VERSION ""

NS_ :

BS_:

BU_: BMS_Ext
VAL_TABLE_ BHVB_State_IMDwarning 1 "IMD未报警" 0 "IMD报警" ;
VAL_TABLE_ BHVB_State_FZ 1 "互锁断开" 0 "互锁闭合" ;
VAL_TABLE_ BHVB_State_HV 1 "电压大于50.2V" 0 "电压小于50.2V" ;
VAL_TABLE_ BHVB_State_intention 1 "意向检测闭合" 0 "意向检测断开" ;
VAL_TABLE_ BHVB_State_BMSwarning 1 "BMS未报警" 0 "BMS报警" ;
VAL_TABLE_ BMS_Cooling_Heating_ValTable 1 "Active" 0 "Inactive" ;
VAL_TABLE_ BatAlmLv_ValTab 3 "3级告警" 2 "2级告警" 1 "1级告警 断电" 0 "无告警" ;
VAL_TABLE_ BatState_ValTab 7 "错误状态" 6 "关机状态" 5 "运行状态" 4 "预充状态" 3 "待机状态" 2 "自检状态" 1 "休眠状态" ;

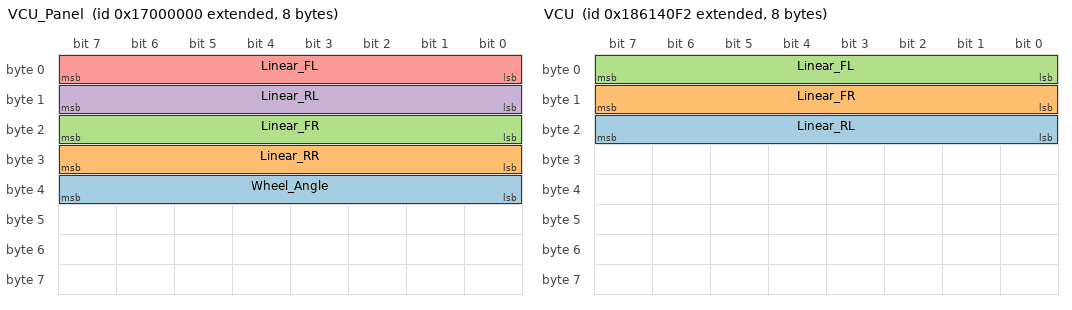
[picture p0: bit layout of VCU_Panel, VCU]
BO_ 2533359616 VCU_Panel: 8 Vector__XXX
 SG_ Wheel_Angle : 32|8@1- (1,0) [0|5000] "" Vector__XXX
 SG_ Linear_RR : 24|8@1- (1,0) [0|5000] "" Vector__XXX
 SG_ Linear_FR : 16|8@1- (1,0) [0|5000] "" Vector__XXX
 SG_ Linear_RL : 8|8@1- (1,0) [0|5000] "" Vector__XXX
 SG_ Linear_FL : 0|8@1- (1,0) [0|5000] "" Vector__XXX

BO_ 2556510450 VCU: 8 Vector__XXX
 SG_ Linear_RL : 16|8@1- (1,0) [0|0] "" Vector__XXX
 SG_ Linear_FR : 8|8@1- (1,0) [0|0] "" Vector__XXX
 SG_ Linear_FL : 0|8@1- (1,0) [0|0] "" Vector__XXX

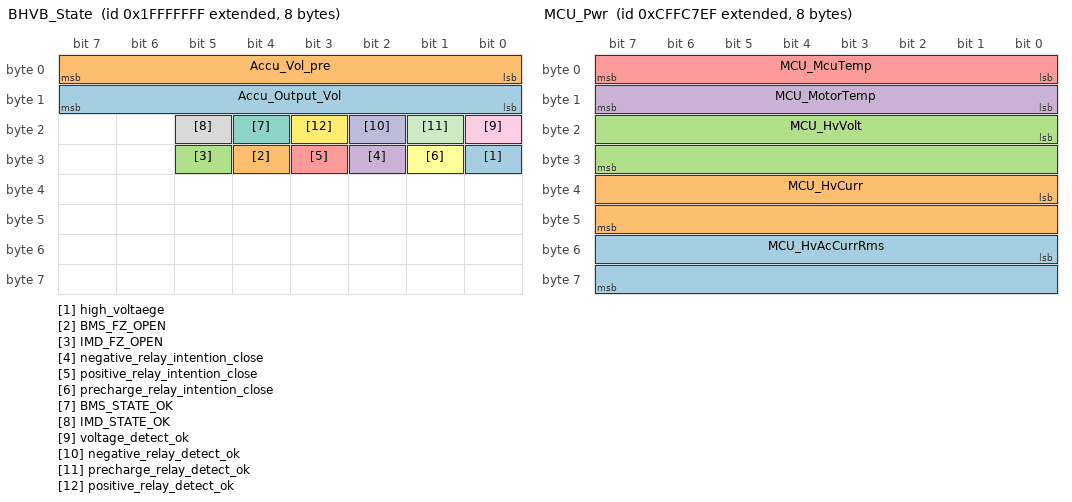
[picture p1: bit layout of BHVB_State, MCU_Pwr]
BO_ 2684354559 BHVB_State: 8 Vector__XXX
 SG_ high_voltaege : 24|1@1- (1,0) [0|0] "" Vector__XXX
 SG_ BMS_FZ_OPEN : 28|1@1- (1,0) [0|0] "" Vector__XXX
 SG_ IMD_FZ_OPEN : 29|1@1- (1,0) [0|0] "" Vector__XXX
 SG_ negative_relay_intention_close : 26|1@1- (1,0) [0|0] "" Vector__XXX
 SG_ positive_relay_intention_close : 27|1@1- (1,0) [0|0] "" Vector__XXX
 SG_ precharge_relay_intention_close : 25|1@1- (1,0) [0|0] "" Vector__XXX
 SG_ BMS_STATE_OK : 20|1@1- (1,0) [0|0] "" Vector__XXX
 SG_ IMD_STATE_OK : 21|1@1- (1,0) [0|0] "" Vector__XXX
 SG_ voltage_detect_ok : 16|1@1- (1,0) [0|0] "" Vector__XXX
 SG_ negative_relay_detect_ok : 18|1@1- (1,0) [0|0] "" Vector__XXX
 SG_ precharge_relay_detect_ok : 17|1@1- (1,0) [0|0] "" Vector__XXX
 SG_ positive_relay_detect_ok : 19|1@1- (1,0) [0|0] "" Vector__XXX
 SG_ Accu_Output_Vol : 8|8@1- (4.9,0) [0|0] "" Vector__XXX
 SG_ Accu_Vol_pre : 0|8@1- (4.9,0) [0|0] "" Vector__XXX

BO_ 2556772595 BMS_HCU_ALM: 8 Vector__XXX
 SG_ BMS_ALM_VCU_OFFLINE : 32|2@1+ (1,0) [0|3] "" Vector__XXX
 SG_ BMS_ALM_PRECHG_FAIL : 36|1@1+ (1,0) [0|3] "" Vector__XXX
 SG_ BMS_ALM_LEAK_OC : 37|2@1+ (1,0) [0|3] "" Vector__XXX
 SG_ BMS_ALM_HVREL_FAIL : 47|1@1+ (1,0) [0|3] "" Vector__XXX
 SG_ BMS_ALM_HALL_BREAK : 46|1@1+ (1,0) [0|3] "" Vector__XXX
 SG_ BMS_ALM_DSCH_OCT : 26|2@1+ (1,0) [0|3] "" Vector__XXX
 SG_ BMS_ALM_DSCH_OCS : 30|2@1+ (1,0) [0|3] "" Vector__XXX
 SG_ BMS_ALM_CHRG_OCT : 28|2@1+ (1,0) [0|3] "" Vector__XXX
 SG_ BMS_ALM_CHRG_OCS : 16|2@1+ (1,0) [0|3] "" Vector__XXX
 SG_ BMS_ALM_CELL_UV : 4|2@1+ (1,0) [0|3] "" Vector__XXX
 SG_ BMS_ALM_CELL_UT : 0|2@1+ (1,0) [0|3] "" Vector__XXX
 SG_ BMS_ALM_CELL_TBK : 14|1@1+ (1,0) [0|3] "" Vector__XXX
 SG_ BMS_ALM_CELL_OV : 6|2@1+ (1,0) [0|3] "" Vector__XXX
 SG_ BMS_ALM_CELL_OT : 2|2@1+ (1,0) [0|3] "" Vector__XXX
 SG_ BMS_ALM_CELL_LBK : 15|1@1+ (1,0) [0|3] "" Vector__XXX
 SG_ BMS_ALM_CELL_DV : 12|2@1+ (1,0) [0|3] "" Vector__XXX
 SG_ BMS_ALM_CELL_DT : 10|2@1+ (1,0) [0|3] "" Vector__XXX
 SG_ BMS_ALM_BSU_OFFLINE : 24|2@1+ (1,0) [0|3] "" Vector__XXX
 SG_ BMS_ALM_BSU_FAULT : 39|1@1+ (1,0) [0|3] "" Vector__XXX
 SG_ BMS_ALM_BMU_FAIL : 34|1@1+ (1,0) [0|3] "" Vector__XXX
 SG_ BMS_ALM_BATT_UV : 22|2@1+ (1,0) [0|3] "" Vector__XXX
 SG_ BMS_ALM_BATT_UC : 18|2@1+ (1,0) [0|3] "" Vector__XXX
 SG_ BMS_ALM_BATT_OV : 8|2@1+ (1,0) [0|3] "" Vector__XXX
 SG_ BMS_ALM_BATT_OC : 20|2@1+ (1,0) [0|3] "" Vector__XXX
 SG_ BMS_ALM_AUX_FAIL : 35|1@1+ (1,0) [0|3] "" Vector__XXX

BO_ 2365573103 MCU_Pwr: 8 Vector__XXX
 SG_ MCU_HvAcCurrRms : 48|16@1+ (0.1,-1600) [-1600|1600] "" Vector__XXX
 SG_ MCU_HvCurr : 32|16@1+ (0.1,-1600) [-1600|1600] "" Vector__XXX
 SG_ MCU_HvVolt : 16|16@1+ (0.1,0) [0|1000] "Volt" Vector__XXX
 SG_ MCU_MotorTemp : 8|8@1+ (1,-50) [-50|205] "" Vector__XXX
 SG_ MCU_McuTemp : 0|8@1+ (1,-50) [-50|205] "celcius" Vector__XXX

BO_ 2365572847 MCU_Stat: 8 Vector__XXX
 SG_ MCU_AlmLv : 56|2@1+ (1,0) [0|3] "" Vector__XXX
 SG_ MCU_IsSelfcheckPass : 55|1@1+ (1,0) [0|1] "" Vector__XXX
 SG_ MCU_IsMotorOvertemp : 49|1@1+ (1,0) [0|1] "" Vector__XXX
 SG_ MCU_IsMcuOvertemp : 48|1@1+ (1,0) [0|1] "" Vector__XXX
 SG_ MCU_IsUnderPowerLim : 47|1@1+ (1,0) [0|1] "" Vector__XXX
 SG_ MCU_IsHvUndervoltage : 46|1@1+ (1,0) [0|1] "" Vector__XXX
 SG_ MCU_IsLvError : 45|1@1+ (1,0) [0|1] "" Vector__XXX
 SG_ MCU_IsHvOvervoltage : 44|1@1+ (1,0) [0|1] "" Vector__XXX
 SG_ MCU_IsOverCurr : 43|1@1+ (1,0) [0|1] "" Vector__XXX
 SG_ MCU_IsRevoloverError : 42|1@1+ (1,0) [0|1] "" Vector__XXX
 SG_ MCU_IsPreChg : 41|1@1+ (1,0) [0|255] "" Vector__XXX
 SG_ MCU_IsReady : 40|1@1+ (1,0) [0|1] "" Vector__XXX
 SG_ MCU_IsMcuNOTActive : 39|1@1+ (1,0) [0|1] "" Vector__XXX
 SG_ MCU_IsZeroLocMode : 36|1@1+ (1,0) [0|1] "" Vector__XXX
 SG_ MCU_IsBrakeMode : 35|1@1+ (1,0) [0|1] "" Vector__XXX
 SG_ MCU_IsSpdMode : 34|1@1+ (1,0) [0|1] "" Vector__XXX
 SG_ MCU_IsTorqMode : 33|1@1+ (1,0) [0|1] "" Vector__XXX
 SG_ MCU_IsFreeMode : 32|1@1+ (1,0) [0|1] "" Vector__XXX
 SG_ MCU_TORQ_RPT : 16|16@1+ (1,0) [0|1000] "1/1000" Vector__XXX
 SG_ MCU_SPD_RPT : 0|16@1+ (0.5,-10000) [-10000|10000] "rpm" Vector__XXX

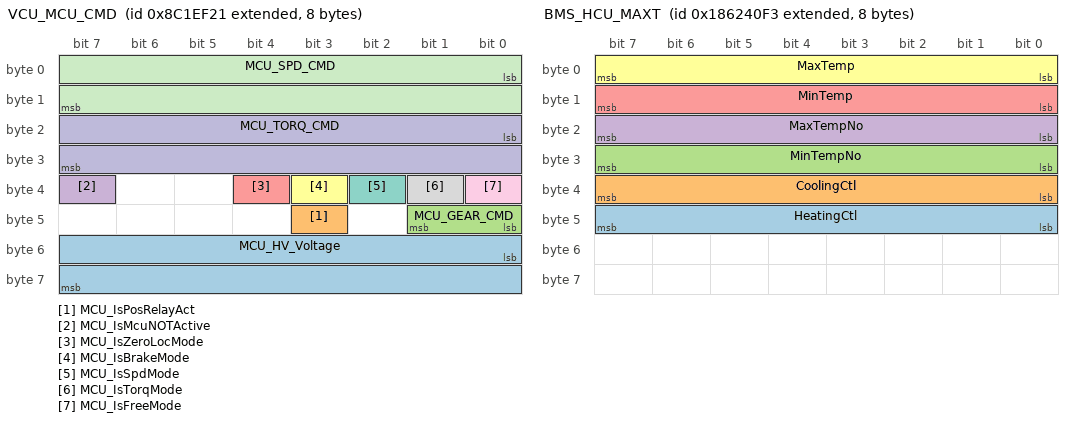
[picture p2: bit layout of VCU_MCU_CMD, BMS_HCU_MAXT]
BO_ 2294411041 VCU_MCU_CMD: 8 Vector__XXX
 SG_ MCU_HV_Voltage : 48|16@1+ (0.1,0) [0|1000] "" Vector__XXX
 SG_ MCU_IsPosRelayAct : 43|1@1+ (1,0) [0|1] "" Vector__XXX
 SG_ MCU_GEAR_CMD : 40|2@1+ (1,0) [0|3] "" Vector__XXX
 SG_ MCU_IsMcuNOTActive : 39|1@1+ (1,0) [0|1] "" Vector__XXX
 SG_ MCU_IsZeroLocMode : 36|1@1+ (1,0) [0|1] "" Vector__XXX
 SG_ MCU_IsBrakeMode : 35|1@1+ (1,0) [0|1] "" Vector__XXX
 SG_ MCU_IsSpdMode : 34|1@1+ (1,0) [0|1] "" Vector__XXX
 SG_ MCU_IsTorqMode : 33|1@1+ (1,0) [0|1] "" Vector__XXX
 SG_ MCU_IsFreeMode : 32|1@1+ (1,0) [0|1] "" Vector__XXX
 SG_ MCU_TORQ_CMD : 16|16@1+ (1,0) [0|1000] "1/1000" Vector__XXX
 SG_ MCU_SPD_CMD : 0|16@1+ (0.5,-10000) [-10000|10000] "rpm" Vector__XXX

BO_ 2556575987 BMS_HCU_MAXT: 8 Vector__XXX
 SG_ HeatingCtl : 47|8@0+ (1,0) [0|1] "" Vector__XXX
 SG_ CoolingCtl : 39|8@0+ (1,0) [0|1] "" Vector__XXX
 SG_ MinTempNo : 31|8@0+ (1,0) [0|255] "" Vector__XXX
 SG_ MaxTempNo : 23|8@0+ (1,0) [0|255] "" Vector__XXX
 SG_ MinTemp : 15|8@0+ (1,-40) [-40|120] "Celsius" Vector__XXX
 SG_ MaxTemp : 7|8@0+ (1,-40) [-40|120] "Celsius" Vector__XXX

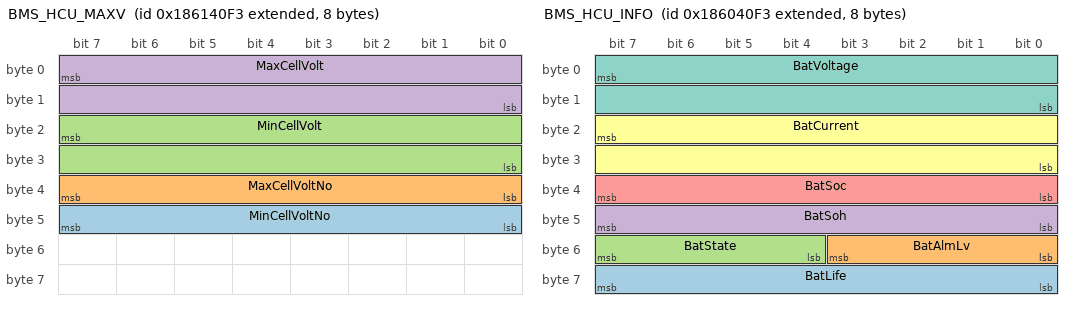
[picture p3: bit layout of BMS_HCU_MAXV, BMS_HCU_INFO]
BO_ 2556510451 BMS_HCU_MAXV: 8 Vector__XXX
 SG_ MinCellVoltNo : 47|8@0+ (1,0) [0|255] "miliVolt" Vector__XXX
 SG_ MaxCellVoltNo : 39|8@0+ (1,0) [0|255] "miliVolt" Vector__XXX
 SG_ MinCellVolt : 23|16@0+ (1,0) [0|5000] "miliVolt" Vector__XXX
 SG_ MaxCellVolt : 7|16@0+ (1,0) [0|5000] "miliVolt" Vector__XXX

BO_ 2556444915 BMS_HCU_INFO: 8 BMS_Ext
 SG_ BatLife : 63|8@0+ (1,0) [0|255] "cycle" Vector__XXX
 SG_ BatAlmLv : 51|4@0+ (1,0) [0|4] "" Vector__XXX
 SG_ BatState : 55|4@0+ (1,0) [0|7] "" Vector__XXX
 SG_ BatSoh : 47|8@0+ (1,0) [0|100] "%" Vector__XXX
 SG_ BatSoc : 39|8@0+ (1,0) [0|100] "%" Vector__XXX
 SG_ BatCurrent : 23|16@0+ (0.1,-1000) [-1000|1000] "Amps" Vector__XXX
 SG_ BatVoltage : 7|16@0+ (0.1,0) [0|900] "Volt" Vector__XXX

CM_ SG_ 2684354559 high_voltaege "电池箱两端电压大于50.2V";
CM_ SG_ 2684354559 BMS_FZ_OPEN "BMS安全回路断开";
CM_ SG_ 2684354559 IMD_FZ_OPEN "IMD安全回路断开
";
CM_ SG_ 2684354559 negative_relay_intention_close "主正继电器意向状态";
CM_ SG_ 2684354559 positive_relay_intention_close "主正继电器意向状态";
CM_ SG_ 2684354559 precharge_relay_intention_close "预充继电器意向状态
";
CM_ SG_ 2684354559 BMS_STATE_OK "BMS Warning
";
CM_ SG_ 2684354559 IMD_STATE_OK "IMD warning";
CM_ SG_ 2684354559 voltage_detect_ok "电压检测电路正常
";
CM_ SG_ 2684354559 negative_relay_detect_ok "主负继电器检测电路正常";
CM_ SG_ 2684354559 precharge_relay_detect_ok "预充继电器检测电路正常";
CM_ SG_ 2684354559 positive_relay_detect_ok "主正继电器检测电路正常";
CM_ SG_ 2684354559 Accu_Output_Vol "电池箱输出电压（主正继电器外侧和主负继电器外侧）";
CM_ SG_ 2684354559 Accu_Vol_pre "电池箱两端电压（预充继电器外侧与主负继电器内侧）";
CM_ SG_ 2365572847 MCU_IsMcuNOTActive "是否为自由模式";
CM_ SG_ 2365572847 MCU_IsZeroLocMode "是否为自由模式";
CM_ SG_ 2365572847 MCU_IsBrakeMode "是否为自由模式";
CM_ SG_ 2365572847 MCU_IsSpdMode "是否为自由模式";
CM_ SG_ 2365572847 MCU_IsTorqMode "是否为自由模式";
CM_ SG_ 2365572847 MCU_IsFreeMode "是否为自由模式";
CM_ SG_ 2365572847 MCU_TORQ_RPT "VCU发送电机转矩指令";
CM_ SG_ 2365572847 MCU_SPD_RPT "VCU发送电机转速指令";
CM_ SG_ 2294411041 MCU_IsPosRelayAct "是否为自由模式";
CM_ SG_ 2294411041 MCU_GEAR_CMD "是否为自由模式";
CM_ SG_ 2294411041 MCU_IsMcuNOTActive "是否为自由模式";
CM_ SG_ 2294411041 MCU_IsZeroLocMode "是否为自由模式";
CM_ SG_ 2294411041 MCU_IsBrakeMode "是否为自由模式";
CM_ SG_ 2294411041 MCU_IsSpdMode "是否为自由模式";
CM_ SG_ 2294411041 MCU_IsTorqMode "是否为自由模式";
CM_ SG_ 2294411041 MCU_IsFreeMode "是否为自由模式";
CM_ SG_ 2294411041 MCU_TORQ_CMD "VCU发送电机转矩指令";
CM_ SG_ 2294411041 MCU_SPD_CMD "VCU发送电机转速指令";
CM_ BO_ 2556575987 "单体温度最值";
CM_ SG_ 2556575987 HeatingCtl "BMS加热状态";
CM_ SG_ 2556575987 CoolingCtl "BMS冷却状态";
CM_ SG_ 2556575987 MinTempNo "最低温度序号";
CM_ SG_ 2556575987 MaxTempNo "最高温度序号";
CM_ SG_ 2556575987 MinTemp "电池单体最低温度";
CM_ SG_ 2556575987 MaxTemp "电池单体最高温度";
CM_ BO_ 2556510451 "单体电压最值";
CM_ SG_ 2556510451 MinCellVoltNo "最低单体电压序号";
CM_ SG_ 2556510451 MaxCellVoltNo "最高单体电压序号";
CM_ SG_ 2556510451 MinCellVolt "最低单体电压";
CM_ SG_ 2556510451 MaxCellVolt "最高单体电压";
CM_ BO_ 2556444915 "BMS信息";
CM_ SG_ 2556444915 BatLife "通信生命信息 通信一次++1";
CM_ SG_ 2556444915 BatAlmLv "动力电池告警级别";
CM_ SG_ 2556444915 BatState "动力电池状态";
CM_ SG_ 2556444915 BatSoh "动力电池SOH";
CM_ SG_ 2556444915 BatSoc "动力电池SOC";
CM_ SG_ 2556444915 BatCurrent "动力电池电流";
CM_ SG_ 2556444915 BatVoltage "动力电池总电压";
BA_DEF_ SG_  "SigType" ENUM  "Default","Range","RangeSigned","ASCII","Discrete","Control","ReferencePGN","DTC","StringDelimiter","StringLength","StringLengthControl","MessageCounter","MessageChecksum";
BA_DEF_ SG_  "GenSigEVName" STRING ;
BA_DEF_ SG_  "GenSigILSupport" ENUM  "No","Yes";
BA_DEF_ SG_  "GenSigSendType" ENUM  "Cyclic","OnWrite","OnWriteWithRepetition","OnChange","OnChangeWithRepetition","IfActive","IfActiveWithRepetition","NoSigSendType";
BA_DEF_ SG_  "GenSigStartValue" INT 0 2147483647;
BA_DEF_ BO_  "GenMsgILSupport" ENUM  "No","Yes";
BA_DEF_ BU_  "NmStationAddress" INT 0 255;
BA_DEF_ BO_  "GenMsgSendType" ENUM  "cyclic","NotUsed","IfActive","NotUsed","NotUsed","NotUsed","NotUsed","NotUsed","noMsgSendType";
BA_DEF_ BO_  "GenMsgRequestable" INT 0 1;
BA_DEF_ BO_  "GenMsgCycleTime" INT 0 3600000;
BA_DEF_  "DBName" STRING ;
BA_DEF_  "BusType" STRING ;
BA_DEF_  "ProtocolType" STRING ;
BA_DEF_ BO_  "VFrameFormat" ENUM  "StandardCAN","ExtendedCAN","reserved","J1939PG";
BA_DEF_DEF_  "SigType" "Default";
BA_DEF_DEF_  "GenSigEVName" "Env@Nodename_@Signame";
BA_DEF_DEF_  "GenSigILSupport" "Yes";
BA_DEF_DEF_  "GenSigSendType" "NoSigSendType";
BA_DEF_DEF_  "GenSigStartValue" 0;
BA_DEF_DEF_  "GenMsgILSupport" "Yes";
BA_DEF_DEF_  "NmStationAddress" 254;
BA_DEF_DEF_  "GenMsgSendType" "noMsgSendType";
BA_DEF_DEF_  "GenMsgRequestable" 1;
BA_DEF_DEF_  "GenMsgCycleTime" 0;
BA_DEF_DEF_  "DBName" "";
BA_DEF_DEF_  "BusType" "CAN";
BA_DEF_DEF_  "ProtocolType" "J1939";
BA_DEF_DEF_  "VFrameFormat" "J1939PG";
BA_ "DBName" "E22_20210411";
BA_ "GenSigStartValue" SG_ 2365573103 MCU_HvAcCurrRms 16000;
BA_ "GenSigStartValue" SG_ 2365573103 MCU_HvCurr 16000;
BA_ "GenSigStartValue" SG_ 2365573103 MCU_MotorTemp 50;
BA_ "GenSigStartValue" SG_ 2365573103 MCU_McuTemp 50;
BA_ "GenSigStartValue" SG_ 2365572847 MCU_SPD_RPT 20000;
BA_ "GenSigStartValue" SG_ 2294411041 MCU_SPD_CMD 20000;
BA_ "GenSigStartValue" SG_ 2556575987 MinTemp 40;
BA_ "GenSigStartValue" SG_ 2556575987 MaxTemp 40;
BA_ "GenSigStartValue" SG_ 2556444915 BatCurrent 10000;
VAL_ 2684354559 high_voltaege 1 "电压大于50.2V" 0 "电压小于50.2V" ;
VAL_ 2684354559 BMS_FZ_OPEN 1 "互锁断开" 0 "互锁闭合" ;
VAL_ 2684354559 IMD_FZ_OPEN 1 "互锁断开" 0 "互锁闭合" ;
VAL_ 2684354559 negative_relay_intention_close 1 "意向检测闭合" 0 "意向检测断开" ;
VAL_ 2684354559 positive_relay_intention_close 1 "意向检测闭合" 0 "意向检测断开" ;
VAL_ 2684354559 precharge_relay_intention_close 1 "意向检测闭合" 0 "意向检测断开" ;
VAL_ 2684354559 BMS_STATE_OK 1 "BMS未报警" 0 "BMS报警" ;
VAL_ 2684354559 IMD_STATE_OK 1 "IMD未报警" 0 "IMD报警" ;
VAL_ 2684354559 voltage_detect_ok 1 "正常" 0 "故障" ;
VAL_ 2684354559 negative_relay_detect_ok 1 "正常" 0 "故障" ;
VAL_ 2684354559 precharge_relay_detect_ok 1 "正常" 0 "故障" ;
VAL_ 2684354559 positive_relay_detect_ok 1 "正常" 0 "故障" ;
VAL_ 2556575987 HeatingCtl 1 "Active" 0 "Inactive" ;
VAL_ 2556575987 CoolingCtl 1 "Active" 0 "Inactive" ;
VAL_ 2556444915 BatAlmLv 3 "3级告警" 2 "2级告警" 1 "1级告警 断电" 0 "无告警" ;
VAL_ 2556444915 BatState 7 "错误状态" 6 "关机状态" 5 "运行状态" 4 "预充状态" 3 "待机状态" 2 "自检状态" 1 "休眠状态" ;
SIG_GROUP_ 2556772595 BMS 1 :;
